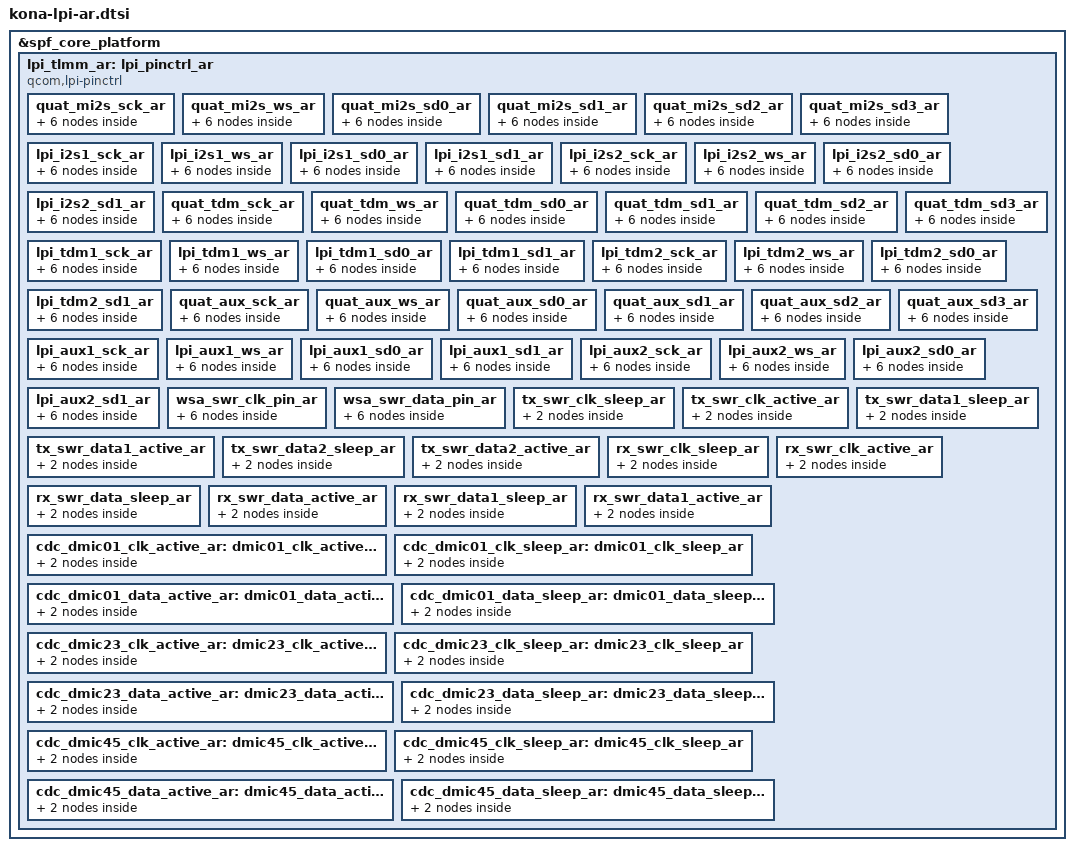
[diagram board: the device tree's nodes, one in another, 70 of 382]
&spf_core_platform {
	lpi_tlmm_ar: lpi_pinctrl_ar {
		compatible = "qcom,lpi-pinctrl";
		reg = <0x33c0000 0x0>;
		qcom,slew-reg = <0x355a000 0x0>;
		qcom,num-gpios = <14>;
		gpio-controller;
		#gpio-cells = <2>;
		qcom,lpi-offset-tbl = <0x00000000>, <0x00001000>,
				      <0x00002000>, <0x00003000>,
				      <0x00004000>, <0x00005000>,
				      <0x00006000>, <0x00007000>,
				      <0x00008000>, <0x00009000>,
				      <0x0000A000>, <0x0000B000>,
				      <0x0000C000>, <0x0000D000>;
		qcom,lpi-slew-offset-tbl = <0x00000000>, <0x00000002>,
					   <0x00000004>, <0x00000008>,
					   <0x0000000A>, <0x0000000C>,
					   <0x00000000>, <0x00000000>,
					   <0x00000000>, <0x00000000>,
					   <0x00000010>, <0x00000012>,
					   <0x00000000>, <0x00000000>;

		clock-names = "lpass_core_hw_vote",
				"lpass_audio_hw_vote";
		clocks = <&lpass_core_hw_vote_ar 0>,
				<&lpass_audio_hw_vote_ar 0>;

		quat_mi2s_sck_ar {
			quat_mi2s_sck_sleep_ar: quat_mi2s_sck_sleep_ar {
				mux {
					pins = "gpio0";
					function = "func2";
				};

				config {
					pins = "gpio0";
					drive-strength = <2>;   /* 2 mA */
					bias-pull-down;         /* PULL DOWN */
					input-enable;
				};
			};

			quat_mi2s_sck_active_ar: quat_mi2s_sck_active_ar {
				mux {
					pins = "gpio0";
					function = "func2";
				};

				config {
					pins = "gpio0";
					drive-strength = <8>;   /* 8 mA */
					bias-disable;           /* NO PULL */
					output-high;
				};
			};
		};

		quat_mi2s_ws_ar {
			quat_mi2s_ws_sleep_ar: quat_mi2s_ws_sleep_ar {
				mux {
					pins = "gpio1";
					function = "func2";
				};

				config {
					pins = "gpio1";
					drive-strength = <2>;   /* 2 mA */
					bias-pull-down;         /* PULL DOWN */
					input-enable;
				};
			};

			quat_mi2s_ws_active_ar: quat_mi2s_ws_active_ar {
				mux {
					pins = "gpio1";
					function = "func2";
				};

				config {
					pins = "gpio1";
					drive-strength = <8>;   /* 8 mA */
					bias-disable;           /* NO PULL */
					output-high;
				};
			};
		};

		quat_mi2s_sd0_ar {
			quat_mi2s_sd0_sleep_ar: quat_mi2s_sd0_sleep_ar {
				mux {
					pins = "gpio2";
					function = "func2";
				};

				config {
					pins = "gpio2";
					drive-strength = <2>;   /* 2 mA */
					bias-pull-down;         /* PULL DOWN */
					input-enable;
				};
			};

			quat_mi2s_sd0_active_ar: quat_mi2s_sd0_active_ar {
				mux {
					pins = "gpio2";
					function = "func2";
				};

				config {
					pins = "gpio2";
					drive-strength = <8>;   /* 8 mA */
					bias-disable;           /* NO PULL */
					output-high;
				};
			};
		};

		quat_mi2s_sd1_ar {
			quat_mi2s_sd1_sleep_ar: quat_mi2s_sd1_sleep_ar {
				mux {
					pins = "gpio3";
					function = "func2";
				};

				config {
					pins = "gpio3";
					drive-strength = <2>;   /* 2 mA */
					bias-pull-down;         /* PULL DOWN */
					input-enable;
				};
			};

			quat_mi2s_sd1_active_ar: quat_mi2s_sd1_active_ar {
				mux {
					pins = "gpio3";
					function = "func2";
				};

				config {
					pins = "gpio3";
					drive-strength = <8>;   /* 8 mA */
					bias-disable;           /* NO PULL */
					output-high;
				};
			};
		};

		quat_mi2s_sd2_ar {
			quat_mi2s_sd2_sleep_ar: quat_mi2s_sd2_sleep_ar {
				mux {
					pins = "gpio4";
					function = "func2";
				};

				config {
					pins = "gpio4";
					drive-strength = <2>;   /* 2 mA */
					bias-pull-down;         /* PULL DOWN */
					input-enable;
				};
			};

			quat_mi2s_sd2_active_ar: quat_mi2s_sd2_active_ar {
				mux {
					pins = "gpio4";
					function = "func2";
				};

				config {
					pins = "gpio4";
					drive-strength = <8>;   /* 8 mA */
					bias-disable;           /* NO PULL */
					output-high;
				};
			};
		};

		quat_mi2s_sd3_ar {
			quat_mi2s_sd3_sleep_ar: quat_mi2s_sd3_sleep_ar {
				mux {
					pins = "gpio5";
					function = "func4";
				};

				config {
					pins = "gpio5";
					drive-strength = <2>;   /* 2 mA */
					bias-pull-down;         /* PULL DOWN */
					input-enable;
				};
			};

			quat_mi2s_sd3_active_ar: quat_mi2s_sd3_active_ar {
				mux {
					pins = "gpio5";
					function = "func4";
				};

				config {
					pins = "gpio5";
					drive-strength = <8>;   /* 8 mA */
					bias-disable;           /* NO PULL */
					output-high;
				};
			};
		};

		lpi_i2s1_sck_ar {
			lpi_i2s1_sck_sleep_ar: lpi_i2s1_sck_sleep_ar {
				mux {
					pins = "gpio6";
					function = "func2";
				};

				config {
					pins = "gpio6";
					drive-strength = <2>;   /* 2 mA */
					bias-pull-down;         /* PULL DOWN */
					input-enable;
				};
			};

			lpi_i2s1_sck_active_ar: lpi_i2s1_sck_active_ar {
				mux {
					pins = "gpio6";
					function = "func2";
				};

				config {
					pins = "gpio6";
					drive-strength = <8>;   /* 8 mA */
					bias-disable;           /* NO PULL */
					output-high;
				};
			};
		};

		lpi_i2s1_ws_ar {
			lpi_i2s1_ws_sleep_ar: lpi_i2s1_ws_sleep_ar {
				mux {
					pins = "gpio7";
					function = "func2";
				};

				config {
					pins = "gpio7";
					drive-strength = <2>;   /* 2 mA */
					bias-pull-down;         /* PULL DOWN */
					input-enable;
				};
			};

			lpi_i2s1_ws_active_ar: lpi_i2s1_ws_active_ar {
				mux {
					pins = "gpio7";
					function = "func2";
				};

				config {
					pins = "gpio7";
					drive-strength = <8>;   /* 8 mA */
					bias-disable;           /* NO PULL */
					output-high;
				};
			};
		};

		lpi_i2s1_sd0_ar {
			lpi_i2s1_sd0_sleep_ar: lpi_i2s1_sd0_sleep_ar {
				mux {
					pins = "gpio8";
					function = "func2";
				};

				config {
					pins = "gpio8";
					drive-strength = <2>;   /* 2 mA */
					bias-pull-down;         /* PULL DOWN */
					input-enable;
				};
			};

			lpi_i2s1_sd0_active_ar: lpi_i2s1_sd0_active_ar {
				mux {
					pins = "gpio8";
					function = "func2";
				};

				config {
					pins = "gpio8";
					drive-strength = <8>;   /* 8 mA */
					bias-disable;           /* NO PULL */
					output-high;
				};
			};
		};

		lpi_i2s1_sd1_ar {
			lpi_i2s1_sd1_sleep_ar: lpi_i2s1_sd1_sleep_ar {
				mux {
					pins = "gpio9";
					function = "func2";
				};

				config {
					pins = "gpio9";
					drive-strength = <2>;   /* 2 mA */
					bias-pull-down;         /* PULL DOWN */
					input-enable;
				};
			};

			lpi_i2s1_sd1_active_ar: lpi_i2s1_sd1_active_ar {
				mux {
					pins = "gpio9";
					function = "func2";
				};

				config {
					pins = "gpio9";
					drive-strength = <8>;   /* 8 mA */
					bias-disable;           /* NO PULL */
					output-high;
				};
			};
		};

		lpi_i2s2_sck_ar {
			lpi_i2s2_sck_sleep_ar: lpi_i2s2_sck_sleep_ar {
				mux {
					pins = "gpio10";
					function = "func1";
				};

				config {
					pins = "gpio10";
					drive-strength = <2>;   /* 2 mA */
					bias-pull-down;         /* PULL DOWN */
					input-enable;
				};
			};

			lpi_i2s2_sck_active_ar: lpi_i2s2_sck_active_ar {
				mux {
					pins = "gpio10";
					function = "func1";
				};

				config {
					pins = "gpio10";
					drive-strength = <8>;   /* 8 mA */
					bias-disable;           /* NO PULL */
					output-high;
				};
			};
		};

		lpi_i2s2_ws_ar {
			lpi_i2s2_ws_sleep_ar: lpi_i2s2_ws_sleep_ar {
				mux {
					pins = "gpio11";
					function = "func1";
				};

				config {
					pins = "gpio11";
					drive-strength = <2>;   /* 2 mA */
					bias-pull-down;         /* PULL DOWN */
					input-enable;
				};
			};

			lpi_i2s2_ws_active_ar: lpi_i2s2_ws_active_ar {
				mux {
					pins = "gpio11";
					function = "func1";
				};

				config {
					pins = "gpio11";
					drive-strength = <8>;   /* 8 mA */
					bias-disable;           /* NO PULL */
					output-high;
				};
			};
		};

		lpi_i2s2_sd0_ar {
			lpi_i2s2_sd0_sleep_ar: lpi_i2s2_sd0_sleep_ar {
				mux {
					pins = "gpio12";
					function = "func2";
				};

				config {
					pins = "gpio12";
					drive-strength = <2>;   /* 2 mA */
					bias-pull-down;         /* PULL DOWN */
					input-enable;
				};
			};

			lpi_i2s2_sd0_active_ar: lpi_i2s2_sd0_active_ar {
				mux {
					pins = "gpio12";
					function = "func2";
				};

				config {
					pins = "gpio12";
					drive-strength = <8>;   /* 8 mA */
					bias-disable;           /* NO PULL */
					output-high;
				};
			};
		};

		lpi_i2s2_sd1_ar {
			lpi_i2s2_sd1_sleep_ar: lpi_i2s2_sd1_sleep_ar {
				mux {
					pins = "gpio13";
					function = "func2";
				};

				config {
					pins = "gpio13";
					drive-strength = <2>;   /* 2 mA */
					bias-pull-down;         /* PULL DOWN */
					input-enable;
				};
			};

			lpi_i2s2_sd1_active_ar: lpi_i2s2_sd1_active_ar {
				mux {
					pins = "gpio13";
					function = "func2";
				};

				config {
					pins = "gpio13";
					drive-strength = <8>;   /* 8 mA */
					bias-disable;           /* NO PULL */
					output-high;
				};
			};
		};

		quat_tdm_sck_ar {
			quat_tdm_sck_sleep_ar: quat_tdm_sck_sleep_ar {
				mux {
					pins = "gpio0";
					function = "func2";
				};

				config {
					pins = "gpio0";
					drive-strength = <2>;   /* 2 mA */
					bias-pull-down;         /* PULL DOWN */
					input-enable;
				};
			};

			quat_tdm_sck_active_ar: quat_tdm_sck_active_ar {
				mux {
					pins = "gpio0";
					function = "func2";
				};

				config {
					pins = "gpio0";
					drive-strength = <8>;   /* 8 mA */
					bias-disable;           /* NO PULL */
					output-high;
				};
			};
		};

		quat_tdm_ws_ar {
			quat_tdm_ws_sleep_ar: quat_tdm_ws_sleep_ar {
				mux {
					pins = "gpio1";
					function = "func2";
				};

				config {
					pins = "gpio1";
					drive-strength = <2>;   /* 2 mA */
					bias-pull-down;         /* PULL DOWN */
					input-enable;
				};
			};

			quat_tdm_ws_active_ar: quat_tdm_ws_active_ar {
				mux {
					pins = "gpio1";
					function = "func2";
				};

				config {
					pins = "gpio1";
					drive-strength = <8>;   /* 8 mA */
					bias-disable;           /* NO PULL */
					output-high;
				};
			};
		};

		quat_tdm_sd0_ar {
			quat_tdm_sd0_sleep_ar: quat_tdm_sd0_sleep_ar {
				mux {
					pins = "gpio2";
					function = "func2";
				};

				config {
					pins = "gpio2";
					drive-strength = <2>;   /* 2 mA */
					bias-pull-down;         /* PULL DOWN */
					input-enable;
				};
			};

			quat_tdm_sd0_active_ar: quat_tdm_sd0_active_ar {
				mux {
					pins = "gpio2";
					function = "func2";
				};

				config {
					pins = "gpio2";
					drive-strength = <8>;   /* 8 mA */
					bias-disable;           /* NO PULL */
					output-high;
				};
			};
		};

		quat_tdm_sd1_ar {
			quat_tdm_sd1_sleep_ar: quat_tdm_sd1_sleep_ar {
				mux {
					pins = "gpio3";
					function = "func2";
				};

				config {
					pins = "gpio3";
					drive-strength = <2>;   /* 2 mA */
					bias-pull-down;         /* PULL DOWN */
					input-enable;
				};
			};

			quat_tdm_sd1_active_ar: quat_tdm_sd1_active_ar {
				mux {
					pins = "gpio3";
					function = "func2";
				};

				config {
					pins = "gpio3";
					drive-strength = <8>;   /* 8 mA */
					bias-disable;           /* NO PULL */
					output-high;
				};
			};
		};

		quat_tdm_sd2_ar {
			quat_tdm_sd2_sleep_ar: quat_tdm_sd2_sleep_ar {
				mux {
					pins = "gpio4";
					function = "func2";
				};

				config {
					pins = "gpio4";
					drive-strength = <2>;   /* 2 mA */
					bias-pull-down;         /* PULL DOWN */
					input-enable;
				};
			};

			quat_tdm_sd2_active_ar: quat_tdm_sd2_active_ar {
				mux {
					pins = "gpio4";
					function = "func2";
				};

				config {
					pins = "gpio4";
					drive-strength = <8>;   /* 8 mA */
					bias-disable;           /* NO PULL */
					output-high;
				};
			};
		};

		quat_tdm_sd3_ar {
			quat_tdm_sd3_sleep_ar: quat_tdm_sd3_sleep_ar {
				mux {
					pins = "gpio5";
					function = "func4";
				};

				config {
					pins = "gpio5";
					drive-strength = <2>;   /* 2 mA */
					bias-pull-down;         /* PULL DOWN */
					input-enable;
				};
			};

			quat_tdm_sd3_active_ar: quat_tdm_sd3_active_ar {
				mux {
					pins = "gpio5";
					function = "func4";
				};

				config {
					pins = "gpio5";
					drive-strength = <8>;   /* 8 mA */
					bias-disable;           /* NO PULL */
					output-high;
				};
			};
		};

		lpi_tdm1_sck_ar {
			lpi_tdm1_sck_sleep_ar: lpi_tdm1_sck_sleep_ar {
				mux {
					pins = "gpio6";
					function = "func2";
				};

				config {
					pins = "gpio6";
					drive-strength = <2>;   /* 2 mA */
					bias-pull-down;         /* PULL DOWN */
					input-enable;
				};
			};

			lpi_tdm1_sck_active_ar: lpi_tdm1_sck_active_ar {
				mux {
					pins = "gpio6";
					function = "func2";
				};

				config {
					pins = "gpio6";
					drive-strength = <8>;   /* 8 mA */
					bias-disable;           /* NO PULL */
					output-high;
				};
			};
		};

		lpi_tdm1_ws_ar {
			lpi_tdm1_ws_sleep_ar: lpi_tdm1_ws_sleep_ar {
				mux {
					pins = "gpio7";
					function = "func2";
				};

				config {
					pins = "gpio7";
					drive-strength = <2>;   /* 2 mA */
					bias-pull-down;         /* PULL DOWN */
					input-enable;
				};
			};

			lpi_tdm1_ws_active_ar: lpi_tdm1_ws_active_ar {
				mux {
					pins = "gpio7";
					function = "func2";
				};

				config {
					pins = "gpio7";
					drive-strength = <8>;   /* 8 mA */
					bias-disable;           /* NO PULL */
					output-high;
				};
			};
		};

		lpi_tdm1_sd0_ar {
			lpi_tdm1_sd0_sleep_ar: lpi_tdm1_sd0_sleep_ar {
				mux {
					pins = "gpio8";
					function = "func2";
				};

				config {
					pins = "gpio8";
					drive-strength = <2>;   /* 2 mA */
					bias-pull-down;         /* PULL DOWN */
					input-enable;
				};
			};

			lpi_tdm1_sd0_active_ar: lpi_tdm1_sd0_active_ar {
				mux {
					pins = "gpio8";
					function = "func2";
				};

				config {
					pins = "gpio8";
					drive-strength = <8>;   /* 8 mA */
					bias-disable;           /* NO PULL */
					output-high;
				};
			};
		};

		lpi_tdm1_sd1_ar {
			lpi_tdm1_sd1_sleep_ar: lpi_tdm1_sd1_sleep_ar {
				mux {
					pins = "gpio9";
					function = "func2";
				};

				config {
					pins = "gpio9";
					drive-strength = <2>;   /* 2 mA */
					bias-pull-down;         /* PULL DOWN */
					input-enable;
				};
			};

			lpi_tdm1_sd1_active_ar: lpi_tdm1_sd1_active_ar {
				mux {
					pins = "gpio9";
					function = "func2";
				};

				config {
					pins = "gpio9";
					drive-strength = <8>;   /* 8 mA */
					bias-disable;           /* NO PULL */
					output-high;
				};
			};
		};

		lpi_tdm2_sck_ar {
			lpi_tdm2_sck_sleep_ar: lpi_tdm2_sck_sleep_ar {
				mux {
					pins = "gpio10";
					function = "func1";
				};

				config {
					pins = "gpio10";
					drive-strength = <2>;   /* 2 mA */
					bias-pull-down;         /* PULL DOWN */
					input-enable;
				};
			};

			lpi_tdm2_sck_active_ar: lpi_tdm2_sck_active_ar {
				mux {
					pins = "gpio10";
					function = "func1";
				};

				config {
					pins = "gpio10";
					drive-strength = <8>;   /* 8 mA */
					bias-disable;           /* NO PULL */
					output-high;
				};
			};
		};

		lpi_tdm2_ws_ar {
			lpi_tdm2_ws_sleep_ar: lpi_tdm2_ws_sleep_ar {
				mux {
					pins = "gpio11";
					function = "func1";
				};

				config {
					pins = "gpio11";
					drive-strength = <2>;   /* 2 mA */
					bias-pull-down;         /* PULL DOWN */
					input-enable;
				};
			};

			lpi_tdm2_ws_active_ar: lpi_tdm2_ws_active_ar {
				mux {
					pins = "gpio11";
					function = "func1";
				};

				config {
					pins = "gpio11";
					drive-strength = <8>;   /* 8 mA */
					bias-disable;           /* NO PULL */
					output-high;
				};
			};
		};

		lpi_tdm2_sd0_ar {
			lpi_tdm2_sd0_sleep_ar: lpi_tdm2_sd0_sleep_ar {
				mux {
					pins = "gpio12";
					function = "func2";
				};

				config {
					pins = "gpio12";
					drive-strength = <2>;   /* 2 mA */
					bias-pull-down;         /* PULL DOWN */
					input-enable;
				};
			};

			lpi_tdm2_sd0_active_ar: lpi_tdm2_sd0_active_ar {
				mux {
					pins = "gpio12";
					function = "func2";
				};

				config {
					pins = "gpio12";
					drive-strength = <8>;   /* 8 mA */
					bias-disable;           /* NO PULL */
					output-high;
				};
			};
		};

		lpi_tdm2_sd1_ar {
			lpi_tdm2_sd1_sleep_ar: lpi_tdm2_sd1_sleep_ar {
				mux {
					pins = "gpio13";
					function = "func2";
				};

				config {
					pins = "gpio13";
					drive-strength = <2>;   /* 2 mA */
					bias-pull-down;         /* PULL DOWN */
					input-enable;
				};
			};

			lpi_tdm2_sd1_active_ar: lpi_tdm2_sd1_active_ar {
				mux {
					pins = "gpio13";
					function = "func2";
				};

				config {
					pins = "gpio13";
					drive-strength = <8>;   /* 8 mA */
					bias-disable;           /* NO PULL */
					output-high;
				};
			};
		};

		quat_aux_sck_ar {
			quat_aux_sck_sleep_ar: quat_aux_sck_sleep_ar {
				mux {
					pins = "gpio0";
					function = "func2";
				};

				config {
					pins = "gpio0";
					drive-strength = <2>;   /* 2 mA */
					bias-pull-down;         /* PULL DOWN */
					input-enable;
				};
			};

			quat_aux_sck_active_ar: quat_aux_sck_active_ar {
				mux {
					pins = "gpio0";
					function = "func2";
				};

				config {
					pins = "gpio0";
					drive-strength = <8>;   /* 8 mA */
					bias-disable;           /* NO PULL */
					output-high;
				};
			};
		};

		quat_aux_ws_ar {
			quat_aux_ws_sleep_ar: quat_aux_ws_sleep_ar {
				mux {
					pins = "gpio1";
					function = "func2";
				};

				config {
					pins = "gpio1";
					drive-strength = <2>;   /* 2 mA */
					bias-pull-down;         /* PULL DOWN */
					input-enable;
				};
			};

			quat_aux_ws_active_ar: quat_aux_ws_active_ar {
				mux {
					pins = "gpio1";
					function = "func2";
				};

				config {
					pins = "gpio1";
					drive-strength = <8>;   /* 8 mA */
					bias-disable;           /* NO PULL */
					output-high;
				};
			};
		};

		quat_aux_sd0_ar {
			quat_aux_sd0_sleep_ar: quat_aux_sd0_sleep_ar {
				mux {
					pins = "gpio2";
					function = "func2";
				};

				config {
					pins = "gpio2";
					drive-strength = <2>;   /* 2 mA */
					bias-pull-down;         /* PULL DOWN */
					input-enable;
				};
			};

			quat_aux_sd0_active_ar: quat_aux_sd0_active_ar {
				mux {
					pins = "gpio2";
					function = "func2";
				};

				config {
					pins = "gpio2";
					drive-strength = <8>;   /* 8 mA */
					bias-disable;           /* NO PULL */
					output-high;
				};
			};
		};

		quat_aux_sd1_ar {
			quat_aux_sd1_sleep_ar: quat_aux_sd1_sleep_ar {
				mux {
					pins = "gpio3";
					function = "func2";
				};

				config {
					pins = "gpio3";
					drive-strength = <2>;   /* 2 mA */
					bias-pull-down;         /* PULL DOWN */
					input-enable;
				};
			};

			quat_aux_sd1_active_ar: quat_aux_sd1_active_ar {
				mux {
					pins = "gpio3";
					function = "func2";
				};

				config {
					pins = "gpio3";
					drive-strength = <8>;   /* 8 mA */
					bias-disable;           /* NO PULL */
					output-high;
				};
			};
		};

		quat_aux_sd2_ar {
			quat_aux_sd2_sleep_ar: quat_aux_sd2_sleep_ar {
				mux {
					pins = "gpio4";
					function = "func2";
				};

				config {
					pins = "gpio4";
					drive-strength = <2>;   /* 2 mA */
					bias-pull-down;         /* PULL DOWN */
					input-enable;
				};
			};

			quat_aux_sd2_active_ar: quat_aux_sd2_active_ar {
				mux {
					pins = "gpio4";
					function = "func2";
				};

				config {
					pins = "gpio4";
					drive-strength = <8>;   /* 8 mA */
					bias-disable;           /* NO PULL */
					output-high;
				};
			};
		};

		quat_aux_sd3_ar {
			quat_aux_sd3_sleep_ar: quat_aux_sd3_sleep_ar {
				mux {
					pins = "gpio5";
					function = "func4";
				};

				config {
					pins = "gpio5";
					drive-strength = <2>;   /* 2 mA */
					bias-pull-down;         /* PULL DOWN */
					input-enable;
				};
			};

			quat_aux_sd3_active_ar: quat_aux_sd3_active_ar {
				mux {
					pins = "gpio5";
					function = "func4";
				};

				config {
					pins = "gpio5";
					drive-strength = <8>;   /* 8 mA */
					bias-disable;           /* NO PULL */
					output-high;
				};
			};
		};

		lpi_aux1_sck_ar {
			lpi_aux1_sck_sleep_ar: lpi_aux1_sck_sleep_ar {
				mux {
					pins = "gpio6";
					function = "func2";
				};

				config {
					pins = "gpio6";
					drive-strength = <2>;   /* 2 mA */
					bias-pull-down;         /* PULL DOWN */
					input-enable;
				};
			};

			lpi_aux1_sck_active_ar: lpi_aux1_sck_active_ar {
				mux {
					pins = "gpio6";
					function = "func2";
				};

				config {
					pins = "gpio6";
					drive-strength = <8>;   /* 8 mA */
					bias-disable;           /* NO PULL */
					output-high;
				};
			};
		};

		lpi_aux1_ws_ar {
			lpi_aux1_ws_sleep_ar: lpi_aux1_ws_sleep_ar {
				mux {
					pins = "gpio7";
					function = "func2";
				};

				config {
					pins = "gpio7";
					drive-strength = <2>;   /* 2 mA */
					bias-pull-down;         /* PULL DOWN */
					input-enable;
				};
			};

			lpi_aux1_ws_active_ar: lpi_aux1_ws_active_ar {
				mux {
					pins = "gpio7";
					function = "func2";
				};

				config {
					pins = "gpio7";
					drive-strength = <8>;   /* 8 mA */
					bias-disable;           /* NO PULL */
					output-high;
				};
			};
		};

		lpi_aux1_sd0_ar {
			lpi_aux1_sd0_sleep_ar: lpi_aux1_sd0_sleep_ar {
				mux {
					pins = "gpio8";
					function = "func2";
				};

				config {
					pins = "gpio8";
					drive-strength = <2>;   /* 2 mA */
					bias-pull-down;         /* PULL DOWN */
					input-enable;
				};
			};

			lpi_aux1_sd0_active_ar: lpi_aux1_sd0_active_ar {
				mux {
					pins = "gpio8";
					function = "func2";
				};

				config {
					pins = "gpio8";
					drive-strength = <8>;   /* 8 mA */
					bias-disable;           /* NO PULL */
					output-high;
				};
			};
		};

		lpi_aux1_sd1_ar {
			lpi_aux1_sd1_sleep_ar: lpi_aux1_sd1_sleep_ar {
				mux {
					pins = "gpio9";
					function = "func2";
				};

				config {
					pins = "gpio9";
					drive-strength = <2>;   /* 2 mA */
					bias-pull-down;         /* PULL DOWN */
					input-enable;
				};
			};

			lpi_aux1_sd1_active_ar: lpi_aux1_sd1_active_ar {
				mux {
					pins = "gpio9";
					function = "func2";
				};

				config {
					pins = "gpio9";
					drive-strength = <8>;   /* 8 mA */
					bias-disable;           /* NO PULL */
					output-high;
				};
			};
		};

		lpi_aux2_sck_ar {
			lpi_aux2_sck_sleep_ar: lpi_aux2_sck_sleep_ar {
				mux {
					pins = "gpio10";
					function = "func1";
				};

				config {
					pins = "gpio10";
					drive-strength = <2>;   /* 2 mA */
					bias-pull-down;         /* PULL DOWN */
					input-enable;
				};
			};

			lpi_aux2_sck_active_ar: lpi_aux2_sck_active_ar {
				mux {
					pins = "gpio10";
					function = "func1";
				};

				config {
					pins = "gpio10";
					drive-strength = <8>;   /* 8 mA */
					bias-disable;           /* NO PULL */
					output-high;
				};
			};
		};

		lpi_aux2_ws_ar {
			lpi_aux2_ws_sleep_ar: lpi_aux2_ws_sleep_ar {
				mux {
					pins = "gpio11";
					function = "func1";
				};

				config {
					pins = "gpio11";
					drive-strength = <2>;   /* 2 mA */
					bias-pull-down;         /* PULL DOWN */
					input-enable;
				};
			};

			lpi_aux2_ws_active_ar: lpi_aux2_ws_active_ar {
				mux {
					pins = "gpio11";
					function = "func1";
				};

				config {
					pins = "gpio11";
					drive-strength = <8>;   /* 8 mA */
					bias-disable;           /* NO PULL */
					output-high;
				};
			};
		};

		lpi_aux2_sd0_ar {
			lpi_aux2_sd0_sleep_ar: lpi_aux2_sd0_sleep_ar {
				mux {
					pins = "gpio12";
					function = "func2";
				};

				config {
					pins = "gpio12";
					drive-strength = <2>;   /* 2 mA */
					bias-pull-down;         /* PULL DOWN */
					input-enable;
				};
			};

			lpi_aux2_sd0_active_ar: lpi_aux2_sd0_active_ar {
				mux {
					pins = "gpio12";
					function = "func2";
				};

				config {
					pins = "gpio12";
					drive-strength = <8>;   /* 8 mA */
					bias-disable;           /* NO PULL */
					output-high;
				};
			};
		};

		lpi_aux2_sd1_ar {
			lpi_aux2_sd1_sleep_ar: lpi_aux2_sd1_sleep_ar {
				mux {
					pins = "gpio13";
					function = "func2";
				};

				config {
					pins = "gpio13";
					drive-strength = <2>;   /* 2 mA */
					bias-pull-down;         /* PULL DOWN */
					input-enable;
				};
			};

			lpi_aux2_sd1_active_ar: lpi_aux2_sd1_active_ar {
				mux {
					pins = "gpio13";
					function = "func2";
				};

				config {
					pins = "gpio13";
					drive-strength = <8>;   /* 8 mA */
					bias-disable;           /* NO PULL */
					output-high;
				};
			};
		};

		wsa_swr_clk_pin_ar {
			wsa_swr_clk_sleep_ar: wsa_swr_clk_sleep_ar {
				mux {
					pins = "gpio10";
					function = "func2";
				};

				config {
					pins = "gpio10";
					drive-strength = <2>;
					input-enable;
					bias-pull-down;
				};
			};

			wsa_swr_clk_active_ar: wsa_swr_clk_active_ar {
				mux {
					pins = "gpio10";
					function = "func2";
				};

				config {
					pins = "gpio10";
					drive-strength = <2>;
					slew-rate = <1>;
					bias-disable;
				};
			};
		};

		wsa_swr_data_pin_ar {
			wsa_swr_data_sleep_ar: wsa_swr_data_sleep_ar {
				mux {
					pins = "gpio11";
					function = "func2";
				};

				config {
					pins = "gpio11";
					drive-strength = <2>;
					input-enable;
					bias-pull-down;
				};
			};

			wsa_swr_data_active_ar: wsa_swr_data_active_ar {
				mux {
					pins = "gpio11";
					function = "func2";
				};

				config {
					pins = "gpio11";
					drive-strength = <2>;
					slew-rate = <1>;
					bias-bus-hold;
				};
			};
		};

		tx_swr_clk_sleep_ar: tx_swr_clk_sleep_ar {
			mux {
				pins = "gpio0";
				function = "func1";
				input-enable;
				bias-pull-down;
			};

			config {
				pins = "gpio0";
				drive-strength = <2>;
			};
		};

		tx_swr_clk_active_ar: tx_swr_clk_active_ar {
			mux {
				pins = "gpio0";
				function = "func1";
			};

			config {
				pins = "gpio0";
				drive-strength = <2>;
				slew-rate = <1>;
				bias-disable;
			};
		};

		tx_swr_data1_sleep_ar: tx_swr_data1_sleep_ar {
			mux {
				pins = "gpio1";
				function = "func1";
			};

			config {
				pins = "gpio1";
				drive-strength = <2>;
				input-enable;
				bias-bus-hold;
			};
		};

		tx_swr_data1_active_ar: tx_swr_data1_active_ar {
			mux {
				pins = "gpio1";
				function = "func1";
			};

			config {
				pins = "gpio1";
				drive-strength = <2>;
				slew-rate = <1>;
				bias-bus-hold;
			};
		};

		tx_swr_data2_sleep_ar: tx_swr_data2_sleep_ar {
			mux {
				pins = "gpio2";
				function = "func1";
			};

			config {
				pins = "gpio2";
				drive-strength = <2>;
				input-enable;
				bias-pull-down;
			};
		};

		tx_swr_data2_active_ar: tx_swr_data2_active_ar {
			mux {
				pins = "gpio2";
				function = "func1";
			};

			config {
				pins = "gpio2";
				drive-strength = <2>;
				slew-rate = <1>;
				bias-bus-hold;
			};
		};

		rx_swr_clk_sleep_ar: rx_swr_clk_sleep_ar {
			mux {
				pins = "gpio3";
				function = "func1";
			};

			config {
				pins = "gpio3";
				drive-strength = <2>;
				input-enable;
				bias-pull-down;
			};
		};

		rx_swr_clk_active_ar: rx_swr_clk_active_ar {
			mux {
				pins = "gpio3";
				function = "func1";
			};

			config {
				pins = "gpio3";
				drive-strength = <2>;
				slew-rate = <1>;
				bias-disable;
			};
		};

		rx_swr_data_sleep_ar: rx_swr_data_sleep_ar {
			mux {
				pins = "gpio4";
				function = "func1";
			};

			config {
				pins = "gpio4";
				drive-strength = <2>;
				input-enable;
				bias-pull-down;
			};
		};

		rx_swr_data_active_ar: rx_swr_data_active_ar {
			mux {
				pins = "gpio4";
				function = "func1";
			};

			config {
				pins = "gpio4";
				drive-strength = <2>;
				slew-rate = <1>;
				bias-bus-hold;
			};
		};

		rx_swr_data1_sleep_ar: rx_swr_data1_sleep_ar {
			mux {
				pins = "gpio5";
				function = "func2";
			};

			config {
				pins = "gpio5";
				drive-strength = <2>;
				input-enable;
				bias-pull-down;
			};
		};

		rx_swr_data1_active_ar: rx_swr_data1_active_ar {
			mux {
				pins = "gpio5";
				function = "func2";
			};

			config {
				pins = "gpio5";
				drive-strength = <2>;
				slew-rate = <1>;
				bias-bus-hold;
			};
		};

		cdc_dmic01_clk_active_ar: dmic01_clk_active_ar {
			mux {
				pins = "gpio6";
				function = "func1";
			};

			config {
				pins = "gpio6";
				drive-strength = <8>;
				output-high;
			};
		};

		cdc_dmic01_clk_sleep_ar: dmic01_clk_sleep_ar {
			mux {
				pins = "gpio6";
				function = "func1";
			};

			config {
				pins = "gpio6";
				drive-strength = <2>;
				bias-disable;
				output-low;
			};
		};

		cdc_dmic01_data_active_ar: dmic01_data_active_ar {
			mux {
				pins = "gpio7";
				function = "func1";
			};

			config {
				pins = "gpio7";
				drive-strength = <8>;
				input-enable;
			};
		};

		cdc_dmic01_data_sleep_ar: dmic01_data_sleep_ar {
			mux {
				pins = "gpio7";
				function = "func1";
			};

			config {
				pins = "gpio7";
				drive-strength = <2>;
				pull-down;
				input-enable;
			};
		};

		cdc_dmic23_clk_active_ar: dmic23_clk_active_ar {
			mux {
				pins = "gpio8";
				function = "func1";
			};

			config {
				pins = "gpio8";
				drive-strength = <8>;
				output-high;
			};
		};

		cdc_dmic23_clk_sleep_ar: dmic23_clk_sleep_ar {
			mux {
				pins = "gpio8";
				function = "func1";
			};

			config {
				pins = "gpio8";
				drive-strength = <2>;
				bias-disable;
				output-low;
			};
		};

		cdc_dmic23_data_active_ar: dmic23_data_active_ar {
			mux {
				pins = "gpio9";
				function = "func1";
			};

			config {
				pins = "gpio9";
				drive-strength = <8>;
				input-enable;
			};
		};

		cdc_dmic23_data_sleep_ar: dmic23_data_sleep_ar {
			mux {
				pins = "gpio9";
				function = "func1";
			};

			config {
				pins = "gpio9";
				drive-strength = <2>;
				pull-down;
				input-enable;
			};
		};

		cdc_dmic45_clk_active_ar: dmic45_clk_active_ar {
			mux {
				pins = "gpio12";
				function = "func1";
			};

			config {
				pins = "gpio12";
				drive-strength = <8>;
				output-high;
			};
		};

		cdc_dmic45_clk_sleep_ar: dmic45_clk_sleep_ar {
			mux {
				pins = "gpio12";
				function = "func1";
			};

			config {
				pins = "gpio12";
				drive-strength = <2>;
				bias-disable;
				output-low;
			};
		};

		cdc_dmic45_data_active_ar: dmic45_data_active_ar {
			mux {
				pins = "gpio13";
				function = "func1";
			};

			config {
				pins = "gpio13";
				drive-strength = <8>;
				input-enable;
			};
		};

		cdc_dmic45_data_sleep_ar: dmic45_data_sleep_ar {
			mux {
				pins = "gpio13";
				function = "func1";
			};

			config {
				pins = "gpio13";
				drive-strength = <2>;
				pull-down;
				input-enable;
			};
		};
	};
};
